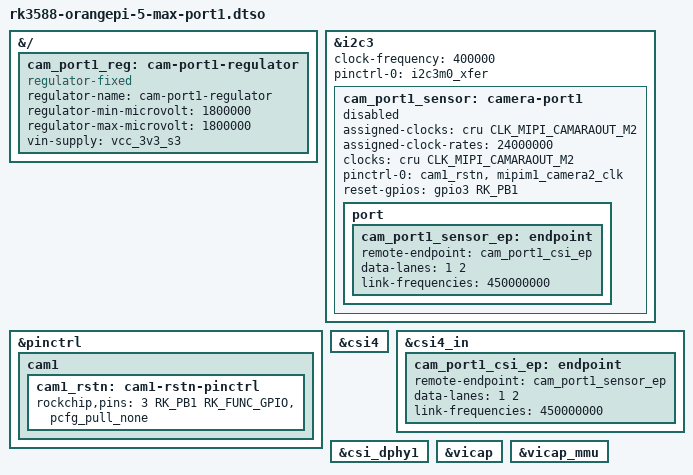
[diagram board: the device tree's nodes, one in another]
// SPDX-License-Identifier: (GPL-2.0+ OR MIT)
/*
 * Orange Pi 5 Max CAM1 (port1): Inno CSI D-PHY1 + CSI4 on i2c3.
 *
 * Publishes cam_port1_sensor, cam_port1_sensor_ep, cam_port1_csi_ep,
 * and cam_port1_reg. The sensor node stays disabled until a sensor overlay
 * enables it. Pins are from the vendor tree for this board.
 */

/dts-v1/;
/plugin/;

#include <dt-bindings/clock/rockchip,rk3588-cru.h>
#include <dt-bindings/gpio/gpio.h>
#include <dt-bindings/pinctrl/rockchip.h>

&{/} {
	cam_port1_reg: cam-port1-regulator {
		compatible = "regulator-fixed";
		regulator-name = "cam-port1-regulator";
		regulator-min-microvolt = <1800000>;
		regulator-max-microvolt = <1800000>;
		vin-supply = <&vcc_3v3_s3>;
	};
};

&i2c3 {
	#address-cells = <1>;
	#size-cells = <0>;
	clock-frequency = <400000>;
	pinctrl-names = "default";
	pinctrl-0 = <&i2c3m0_xfer>;
	status = "okay";

	cam_port1_sensor: camera-port1 {
		status = "disabled";
		assigned-clocks = <&cru CLK_MIPI_CAMARAOUT_M2>;
		assigned-clock-rates = <24000000>;
		clocks = <&cru CLK_MIPI_CAMARAOUT_M2>;
		pinctrl-names = "default";
		pinctrl-0 = <&cam1_rstn &mipim1_camera2_clk>;
		reset-gpios = <&gpio3 RK_PB1 GPIO_ACTIVE_HIGH>;

		port {
			cam_port1_sensor_ep: endpoint {
				remote-endpoint = <&cam_port1_csi_ep>;
				data-lanes = <1 2>;
				link-frequencies = /bits/ 64 <450000000>;
			};
		};
	};
};

&pinctrl {
	cam1 {
		cam1_rstn: cam1-rstn-pinctrl {
			rockchip,pins = <3 RK_PB1 RK_FUNC_GPIO &pcfg_pull_none>;
		};
	};
};

&csi4 {
	status = "okay";
};

&csi4_in {
	cam_port1_csi_ep: endpoint {
		remote-endpoint = <&cam_port1_sensor_ep>;
		data-lanes = <1 2>;
		link-frequencies = /bits/ 64 <450000000>;
	};
};

&csi_dphy1 {
	status = "okay";
};

&vicap {
	status = "okay";
};

&vicap_mmu {
	status = "okay";
};
